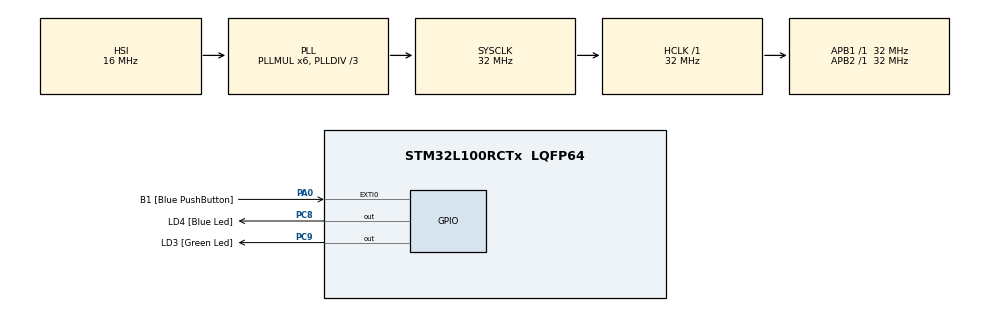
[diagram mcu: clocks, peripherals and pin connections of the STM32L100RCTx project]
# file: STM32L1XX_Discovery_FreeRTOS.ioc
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FREERTOS.Tasks01=defaultTask,0,128,StartDefaultTask,Default
FREERTOS.configGENERATE_RUN_TIME_STATS=0
FREERTOS.configIDLE_SHOULD_YIELD=0
FREERTOS.configTOTAL_HEAP_SIZE=4096
Mcu.Family=STM32L1
Mcu.Name=STM32L100RCTx
Mcu.Package=LQFP64
NVIC.PriorityGroup=NVIC_PRIORITYGROUP_4
PA0-WKUP1.GPIO_Label=B1 [Blue PushButton]
PA0-WKUP1.GPIO_ModeDefaultEXTI=GPIO_MODE_EVT_RISING
PA0-WKUP1.Signal=GPXTI0
PA13.GPIO_Label=SWDIO
PA13.Signal=SYS_JTMS-SWDIO
PA14.GPIO_Label=SWCLK
PA14.Signal=SYS_JTCK-SWCLK
PB3.GPIO_Label=SWO
PB3.Signal=SYS_JTDO-TRACESWO
PC14-OSC32_IN.GPIO_Label=PC14-OSC32_IN
PC14-OSC32_IN.Signal=RCC_OSC32_IN
PC15-OSC32_OUT.GPIO_Label=PC15-OSC32_OUT
PC15-OSC32_OUT.Signal=RCC_OSC32_OUT
PC8.GPIO_Label=LD4 [Blue Led]
PC8.Signal=GPIO_Output
PC9.GPIO_Label=LD3 [Green Led]
PC9.Signal=GPIO_Output
PH0-OSC_IN.GPIO_Label=PH0-OSC_IN
PH0-OSC_IN.Signal=RCC_OSC_IN
PH1-OSC_OUT.GPIO_Label=PH1-OSC_OUT
PH1-OSC_OUT.Signal=RCC_OSC_OUT
ProjectManager.HeapSize=0x200
ProjectManager.StackSize=0x400
ProjectManager.TargetToolchain=SW4STM32
RCC.AHBFreq_Value=32000000
RCC.APB1Freq_Value=32000000
RCC.APB1TimFreq_Value=32000000
RCC.APB2Freq_Value=32000000
RCC.APB2TimFreq_Value=32000000
RCC.HCLKFreq_Value=32000000
RCC.HSE_VALUE=8000000
RCC.HSI_VALUE=16000000
RCC.LSEState=RCC_LSE_ON
RCC.LSE_VALUE=32768
RCC.MSI_VALUE=2097000
RCC.PLLDIV=RCC_PLL_DIV3
RCC.PLLMUL=RCC_PLL_MUL6
RCC.RTCClockSelectionVirtual=RCC_RTCCLKSOURCE_LSE
RCC.SYSCLKFreq_VALUE=32000000
RCC.SYSCLKSource=RCC_SYSCLKSOURCE_PLLCLK
RCC.USBOutput=48000000
RCC.VCOOutputFreq_Value=96000000
VP_FREERTOS_VS_ENABLE.Mode=Enabled
board=STM32L100C-DISCO

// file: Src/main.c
/**
  ******************************************************************************
  * File Name          : main.c
  * Description        : Main program body
  ******************************************************************************
  *
  * COPYRIGHT(c) 2016 STMicroelectronics
  *
  * Redistribution and use in source and binary forms, with or without modification,
  * are permitted provided that the following conditions are met:
  *   1. Redistributions of source code must retain the above copyright notice,
  *      this list of conditions and the following disclaimer.
  *   2. Redistributions in binary form must reproduce the above copyright notice,
  *      this list of conditions and the following disclaimer in the documentation
  *      and/or other materials provided with the distribution.
  *   3. Neither the name of STMicroelectronics nor the names of its contributors
  *      may be used to endorse or promote products derived from this software
  *      without specific prior written permission.
  *
  * THIS SOFTWARE IS PROVIDED BY THE COPYRIGHT HOLDERS AND CONTRIBUTORS "AS IS"
  * AND ANY EXPRESS OR IMPLIED WARRANTIES, INCLUDING, BUT NOT LIMITED TO, THE
  * IMPLIED WARRANTIES OF MERCHANTABILITY AND FITNESS FOR A PARTICULAR PURPOSE ARE
  * DISCLAIMED. IN NO EVENT SHALL THE COPYRIGHT HOLDER OR CONTRIBUTORS BE LIABLE
  * FOR ANY DIRECT, INDIRECT, INCIDENTAL, SPECIAL, EXEMPLARY, OR CONSEQUENTIAL
  * DAMAGES (INCLUDING, BUT NOT LIMITED TO, PROCUREMENT OF SUBSTITUTE GOODS OR
  * SERVICES; LOSS OF USE, DATA, OR PROFITS; OR BUSINESS INTERRUPTION) HOWEVER
  * CAUSED AND ON ANY THEORY OF LIABILITY, WHETHER IN CONTRACT, STRICT LIABILITY,
  * OR TORT (INCLUDING NEGLIGENCE OR OTHERWISE) ARISING IN ANY WAY OUT OF THE USE
  * OF THIS SOFTWARE, EVEN IF ADVISED OF THE POSSIBILITY OF SUCH DAMAGE.
  *
  ******************************************************************************
  */
#include "stm32l1xx_hal.h"
#include "cmsis_os.h"
#include "gpio.h"

/* USER CODE BEGIN Includes */
#include<stdio.h>
#include<stdlib.h>
/* USER CODE END Includes */

/* USER CODE BEGIN PV */
/* Private variables ---------------------------------------------------------*/
TaskHandle_t T1, T2;
/* USER CODE END PV */

void SystemClock_Config(void);
void Error_Handler(void);
void MX_FREERTOS_Init(void);

/* USER CODE BEGIN PFP */
/* Private function prototypes -----------------------------------------------*/

/* USER CODE END PFP */

/* USER CODE BEGIN 0 */
//Task T1
void taskLED1(void *pvParameters)
{
  while(1)
  {
	HAL_GPIO_TogglePin(GPIOC, LD4_Pin);       //toggle LD4
	printf("Hello from Task-1\n");
	vTaskDelay(500);
  }
}

//Task T2
void taskLED2(void *pvParameters)
{
  while(1)
  {
	HAL_GPIO_TogglePin(GPIOC, LD3_Pin);       //toggle LD3
	printf("Hello from Task-2\n");
	vTaskDelay(250);
  }
}
/* USER CODE END 0 */

int main(void)
{

  /* USER CODE BEGIN 1 */
  BaseType_t retVal;
  initialise_monitor_handles();                   //to enable debug printf()
  /* USER CODE END 1 */

  /* MCU Configuration----------------------------------------------------------*/

  /* Reset of all peripherals, Initializes the Flash interface and the Systick. */
  HAL_Init();

  /* Configure the system clock */
  SystemClock_Config();

  /* Initialize all configured peripherals */
  MX_GPIO_Init();

  /* USER CODE BEGIN 2 */
  //create tasks
  retVal=xTaskCreate(taskLED1, "taskLED1", 128, NULL, configMAX_PRIORITIES-1, &T1);       //higher priority task
  retVal=xTaskCreate(taskLED2, "taskLED2", 128, NULL, configMAX_PRIORITIES-2, &T2);       //lower priority task
  printf("FreeRTOS Program\n");
  /* USER CODE END 2 */

  /* Call init function for freertos objects (in freertos.c) */
  MX_FREERTOS_Init();

  /* Start scheduler */
  osKernelStart();

  /* We should never get here as control is now taken by the scheduler */

  /* Infinite loop */
  while (1)
  {

  }

}

/** System Clock Configuration
*/
void SystemClock_Config(void)
{

  RCC_OscInitTypeDef RCC_OscInitStruct;
  RCC_ClkInitTypeDef RCC_ClkInitStruct;

  __HAL_RCC_PWR_CLK_ENABLE();

  __HAL_PWR_VOLTAGESCALING_CONFIG(PWR_REGULATOR_VOLTAGE_SCALE1);

  RCC_OscInitStruct.OscillatorType = RCC_OSCILLATORTYPE_HSI;
  RCC_OscInitStruct.HSIState = RCC_HSI_ON;
  RCC_OscInitStruct.HSICalibrationValue = 16;
  RCC_OscInitStruct.PLL.PLLState = RCC_PLL_ON;
  RCC_OscInitStruct.PLL.PLLSource = RCC_PLLSOURCE_HSI;
  RCC_OscInitStruct.PLL.PLLMUL = RCC_PLL_MUL6;
  RCC_OscInitStruct.PLL.PLLDIV = RCC_PLL_DIV3;
  if (HAL_RCC_OscConfig(&RCC_OscInitStruct) != HAL_OK)
  {
    Error_Handler();
  }

  RCC_ClkInitStruct.ClockType = RCC_CLOCKTYPE_HCLK|RCC_CLOCKTYPE_SYSCLK
                              |RCC_CLOCKTYPE_PCLK1|RCC_CLOCKTYPE_PCLK2;
  RCC_ClkInitStruct.SYSCLKSource = RCC_SYSCLKSOURCE_PLLCLK;
  RCC_ClkInitStruct.AHBCLKDivider = RCC_SYSCLK_DIV1;
  RCC_ClkInitStruct.APB1CLKDivider = RCC_HCLK_DIV1;
  RCC_ClkInitStruct.APB2CLKDivider = RCC_HCLK_DIV1;
  if (HAL_RCC_ClockConfig(&RCC_ClkInitStruct, FLASH_LATENCY_1) != HAL_OK)
  {
    Error_Handler();
  }

  HAL_SYSTICK_Config(HAL_RCC_GetHCLKFreq()/1000);

  HAL_SYSTICK_CLKSourceConfig(SYSTICK_CLKSOURCE_HCLK);

  /* SysTick_IRQn interrupt configuration */
  HAL_NVIC_SetPriority(SysTick_IRQn, 15, 0);
}

void Error_Handler(void)
{
  while(1)
  {
  }
}

/************************ (C) COPYRIGHT STMicroelectronics *****END OF FILE****/
